# XMC4300 register map
Vendor: Infineon; File version: 1.0.4 (Reference Manual v1.0)
CPU: CM4 r2p0, little endian, MPU, FPU, 6 interrupt priority bits
Registers are 32-bit, read-write, reset 0x0 unless marked. A register's access mark holds for its fields unless they carry their own. Offsets are from the block's base; [hi:lo] are bit positions.

## RTC — Real Time Clock
Base 0x50004A00
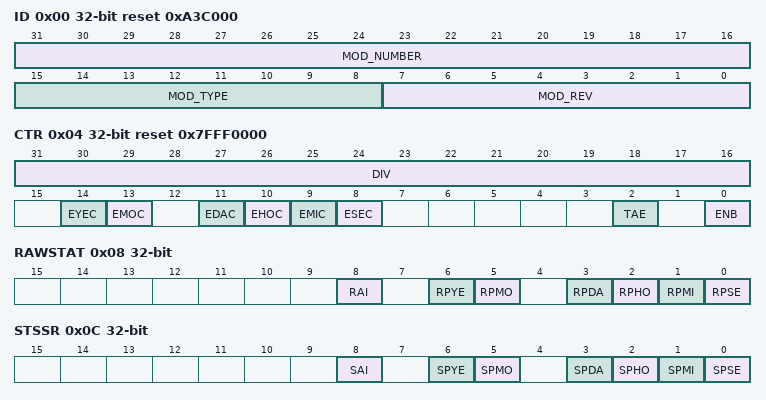
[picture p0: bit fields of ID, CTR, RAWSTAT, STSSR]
0x00 ID ro reset 0xA3C000 (reset mask 0xFFFFFF00) — RTC ID Register
  [31:16] MOD_NUMBER — Module Number
  [15:8] MOD_TYPE — Module Type
  [7:0] MOD_REV — Module Revision
0x04 CTR reset 0x7FFF0000 — RTC Control Register
  [31:16] DIV — RTC Clock Divider Value
  [14] EYEC — Enable Years Comparison for Hibernation Wake-up
  [13] EMOC — Enable Months Comparison for Hibernation Wake-up
  [11] EDAC — Enable Days Comparison for Hibernation Wake-up
  [10] EHOC — Enable Hours Comparison for Hibernation Wake-up
  [9] EMIC — Enable Minutes Comparison for Hibernation Wake-up
  [8] ESEC — Enable Seconds Comparison for Hibernation Wake-up
  [2] TAE — Timer Alarm Enable for Hibernation Wake-up
  [0] ENB — RTC Module Enable
0x08 RAWSTAT ro — RTC Raw Service Request Register
  [8] RAI — Raw Alarm Service Request
  [6] RPYE — Raw Periodic Years Service Request
  [5] RPMO — Raw Periodic Months Service Request
  [3] RPDA — Raw Periodic Days Service Request
  [2] RPHO — Raw Periodic Hours Service Request
  [1] RPMI — Raw Periodic Minutes Service Request
  [0] RPSE — Raw Periodic Seconds Service Request
0x0C STSSR ro — RTC Service Request Status Register
  [8] SAI — Alarm Service Request Status after Masking
  [6] SPYE — Periodic Years Service Request Status after Masking
  [5] SPMO — Periodic Months Service Request Status after Masking
  [3] SPDA — Periodic Days Service Request Status after Masking
  [2] SPHO — Periodic Hours Service Request Status after Masking
  [1] SPMI — Periodic Minutes Service Request Status after Masking
  [0] SPSE — Periodic Seconds Service Request Status after Masking
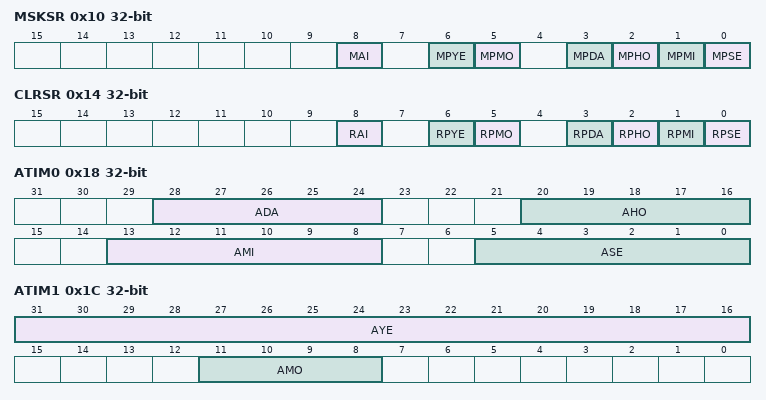
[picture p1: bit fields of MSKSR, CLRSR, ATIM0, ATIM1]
0x10 MSKSR — RTC Service Request Mask Register
  [8] MAI — Alarm Interrupt Mask
  [6] MPYE — Periodic Years Interrupt Mask
  [5] MPMO — Periodic Months Interrupt Mask
  [3] MPDA — Periodic Days Interrupt Mask
  [2] MPHO — Periodic Hours Interrupt Mask
  [1] MPMI — Periodic Minutes Interrupt Mask
  [0] MPSE — Periodic Seconds Interrupt Mask
0x14 CLRSR wo — RTC Clear Service Request Register
  [8] RAI — Alarm Interrupt Clear
  [6] RPYE — Periodic Years Interrupt Clear
  [5] RPMO — Periodic Months Interrupt Clear
  [3] RPDA — Periodic Days Interrupt Clear
  [2] RPHO — Periodic Hours Interrupt Clear
  [1] RPMI — Periodic Minutes Interrupt Clear
  [0] RPSE — Periodic Seconds Interrupt Clear
0x18 ATIM0 — RTC Alarm Time Register 0
  [28:24] ADA — Alarm Days Compare Value
  [20:16] AHO — Alarm Hours Compare Value
  [13:8] AMI — Alarm Minutes Compare Value
  [5:0] ASE — Alarm Seconds Compare Value
0x1C ATIM1 — RTC Alarm Time Register 1
  [31:16] AYE — Alarm Year Compare Value
  [11:8] AMO — Alarm Month Compare Value
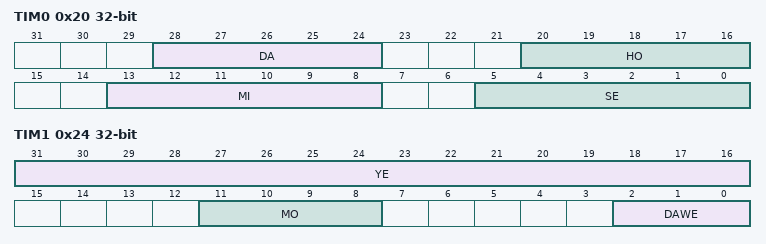
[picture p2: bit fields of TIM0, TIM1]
0x20 TIM0 — RTC Time Register 0
  [28:24] DA — Days Time Value
  [20:16] HO — Hours Time Value
  [13:8] MI — Minutes Time Value
  [5:0] SE — Seconds Time Value
0x24 TIM1 — RTC Time Register 1
  [31:16] YE — Year Time Value
  [11:8] MO — Month Time Value
  [2:0] DAWE — Days of Week Time Value

## SCU_OSC — System Control Unit
Base 0x50004700
0x00 OSCHPSTAT ro — OSC_HP Status Register
  [0] X1D — XTAL1 Data Value
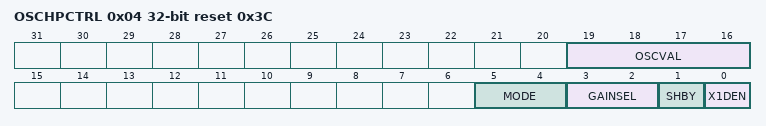
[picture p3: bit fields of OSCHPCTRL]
0x04 OSCHPCTRL reset 0x3C — OSC_HP Control Register
  [19:16] OSCVAL — OSC Frequency Value
  [5:4] MODE — Oscillator Mode
    0=Const_00 (External Crystal Mode and External Input Clock Mode. The oscillator Power-Saving Mode is not entered.); 1=Const_01 (OSC is disabled. The oscillator Power-Saving Mode is not entered.); 2=Const_10 (External Input Clock Mode and the oscillator Power-Saving Mode is entered); 3=Const_11 (OSC is disabled. The oscillator Power-Saving Mode is entered.)
  [3:2] GAINSEL — Oscillator Gain Selection
    0=Const_00 (The gain control is configured for frequencies from 4 MHz to 8 MHz); 1=Const_01 (The gain control is configured for frequencies from 4 MHz to 16 MHz); 2=Const_10 (The gain control is configured for frequencies from 4 MHz to 20 MHz); 3=Const_11 (The gain control is configured for frequencies from 4 MHz to 25 MHz)
  [1] SHBY — Shaper Bypass
    0=Const_0 (The shaper is not bypassed); 1=Const_1 (The shaper is bypassed)
  [0] X1DEN — XTAL1 Data Enable
    0=Const_0 (Bit X1D is not updated); 1=Const_1 (Bit X1D can be updated)
0x0C CLKCALCONST ro — Clock Calibration Constant Register
  [3:0] CALIBCONST — Clock Calibration Constant Value

## Notices in the file
Copyright (c) 2016, Infineon Technologies AG
All rights reserved.
Redistribution and use in source and binary forms, with or without modification,are permitted provided that the
following conditions are met:
Redistributions of source code must retain the above copyright notice, this list of conditions and the following
disclaimer.
Redistributions in binary form must reproduce the above copyright notice, this list of conditions and the following
disclaimer in the documentation and/or other materials provided with the distribution.
Neither the name of the copyright holders nor the names of its contributors may be used to endorse or promote
products derived from this software without specific prior written permission.
THIS SOFTWARE IS PROVIDED BY THE COPYRIGHT HOLDERS AND CONTRIBUTORS "AS IS" AND ANY EXPRESS OR IMPLIED WARRANTIES,
INCLUDING, BUT NOT LIMITED TO, THE IMPLIED WARRANTIES OF MERCHANTABILITY AND FITNESS FOR A PARTICULAR PURPOSE ARE
DISCLAIMED. IN NO EVENT SHALL THE COPYRIGHT HOLDER OR CONTRIBUTORS BE LIABLE  FOR ANY DIRECT, INDIRECT, INCIDENTAL,
SPECIAL, EXEMPLARY, OR CONSEQUENTIAL DAMAGES (INCLUDING, BUT NOT LIMITED TO, PROCUREMENT OF SUBSTITUTE GOODS OR
SERVICES; LOSS OF USE, DATA, OR PROFITS; OR BUSINESS INTERRUPTION) HOWEVER CAUSED AND ON ANY THEORY OF LIABILITY,
WHETHER IN CONTRACT, STRICT LIABILITY,OR TORT (INCLUDING NEGLIGENCE OR OTHERWISE) ARISING IN ANY WAY OUT OF THE USE
OF THIS SOFTWARE, EVEN IF ADVISED OF THE POSSIBILITY OF SUCH DAMAGE.
